# STM32F334C4T6 register map
File version: 1.0
Registers are 32-bit, access not given, reset 0x0 unless marked. A register's access mark holds for its fields unless they carry their own. Offsets are from the block's base; [hi:lo] are bit positions; {n}, {i} and the like mark numbered series; 'fields as' and 'values as' point back to an identical list.

## HRTIM1
Base 0x40017400
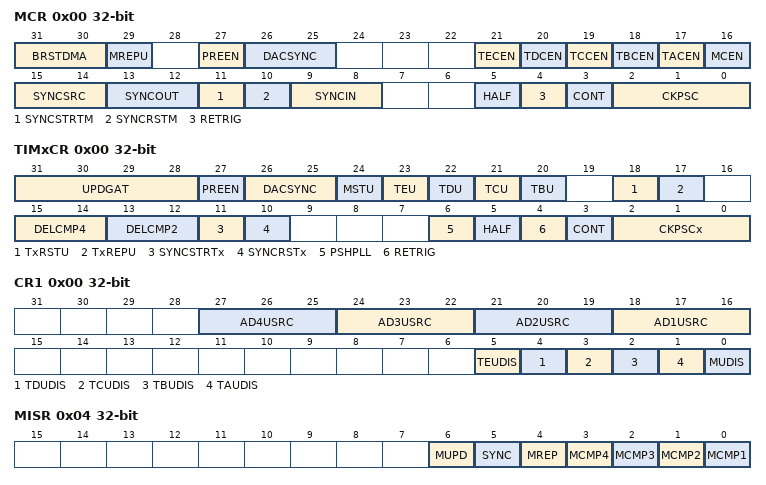
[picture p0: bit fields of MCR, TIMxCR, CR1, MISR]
0x00 MCR
  [31:30] BRSTDMA, [29] MREPU, [27] PREEN, [26:25] DACSYNC, [21] TECEN, [20] TDCEN, [19] TCCEN, [18] TBCEN, [17] TACEN, [16] MCEN, [15:14] SYNCSRC, [13:12] SYNCOUT, [11] SYNCSTRTM, [10] SYNCRSTM, [9:8] SYNCIN, [5] HALF, [4] RETRIG, [3] CONT, [2:0] CKPSC
0x00 TIMxCR
  [31:28] UPDGAT, [27] PREEN, [26:25] DACSYNC, [24] MSTU, [23] TEU, [22] TDU, [21] TCU, [20] TBU, [18] TxRSTU, [17] TxREPU, [15:14] DELCMP4, [13:12] DELCMP2, [11] SYNCSTRTx, [10] SYNCRSTx, [6] PSHPLL, [5] HALF, [4] RETRIG, [3] CONT, [2:0] CKPSCx
0x00 CR1
  [3n+15:3n+13] AD{n}USRC (n=1..4), [5] TEUDIS, [4] TDUDIS, [3] TCUDIS, [2] TBUDIS, [1] TAUDIS, [0] MUDIS
0x04 MISR
  [6] MUPD, [5] SYNC, [4] MREP, [n-1] MCMP{n} (n=1..4)
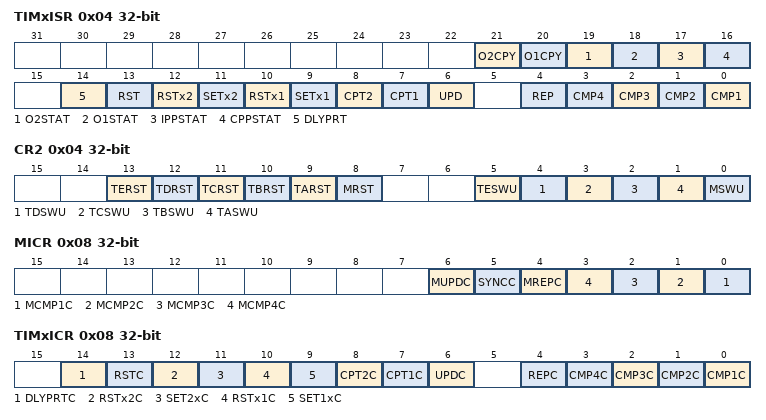
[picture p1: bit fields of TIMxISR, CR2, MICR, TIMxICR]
0x04 TIMxISR
  [21] O2CPY, [20] O1CPY, [19] O2STAT, [18] O1STAT, [17] IPPSTAT, [16] CPPSTAT, [14] DLYPRT, [13] RST, [12] RSTx2, [11] SETx2, [10] RSTx1, [9] SETx1, [8] CPT2, [7] CPT1, [6] UPD, [4] REP, [n-1] CMP{n} (n=1..4)
0x04 CR2
  [13] TERST, [12] TDRST, [11] TCRST, [10] TBRST, [9] TARST, [8] MRST, [5] TESWU, [4] TDSWU, [3] TCSWU, [2] TBSWU, [1] TASWU, [0] MSWU
0x08 MICR
  [6] MUPDC, [5] SYNCC, [4] MREPC, [n-1] MCMP{n}C (n=1..4)
0x08 TIMxICR
  [14] DLYPRTC, [13] RSTC, [12] RSTx2C, [11] SET2xC, [10] RSTx1C, [9] SET1xC, [8] CPT2C, [7] CPT1C, [6] UPDC, [4] REPC, [n-1] CMP{n}C (n=1..4)
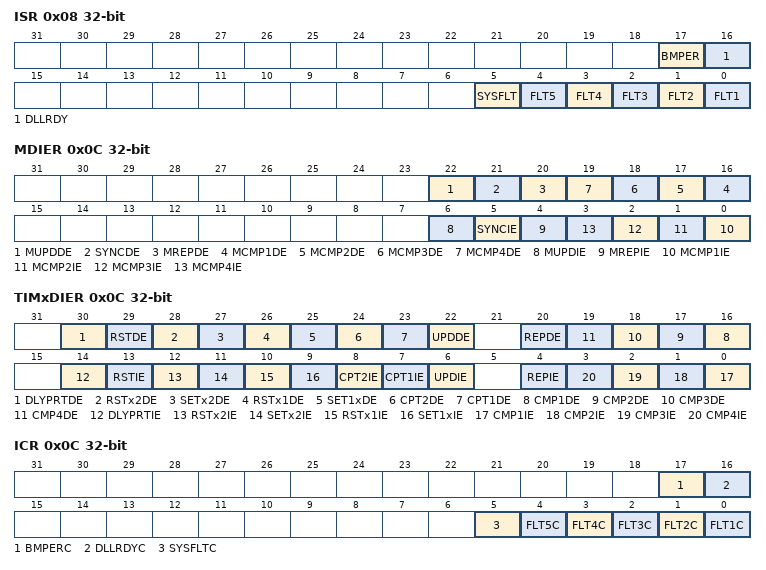
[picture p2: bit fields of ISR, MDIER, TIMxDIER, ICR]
0x08 ISR
  [17] BMPER, [16] DLLRDY, [5] SYSFLT, [n-1] FLT{n} (n=1..5)
0x0C MDIER
  [22] MUPDDE, [21] SYNCDE, [20] MREPDE, [n+15] MCMP{n}DE (n=1..4), [6] MUPDIE, [5] SYNCIE, [4] MREPIE, [n-1] MCMP{n}IE (n=1..4)
0x0C TIMxDIER
  [30] DLYPRTDE, [29] RSTDE, [28] RSTx2DE, [27] SETx2DE, [26] RSTx1DE, [25] SET1xDE, [24] CPT2DE, [23] CPT1DE, [22] UPDDE, [20] REPDE, [n+15] CMP{n}DE (n=1..4), [14] DLYPRTIE, [13] RSTIE, [12] RSTx2IE, [11] SETx2IE, [10] RSTx1IE, [9] SET1xIE, [8] CPT2IE, [7] CPT1IE, [6] UPDIE, [4] REPIE, [n-1] CMP{n}IE (n=1..4)
0x0C ICR
  [17] BMPERC, [16] DLLRDYC, [5] SYSFLTC, [n-1] FLT{n}C (n=1..5)
0x10 MCNTR
  [15:0] MCNT
0x10 CNTxR
  [15:0] CNTx
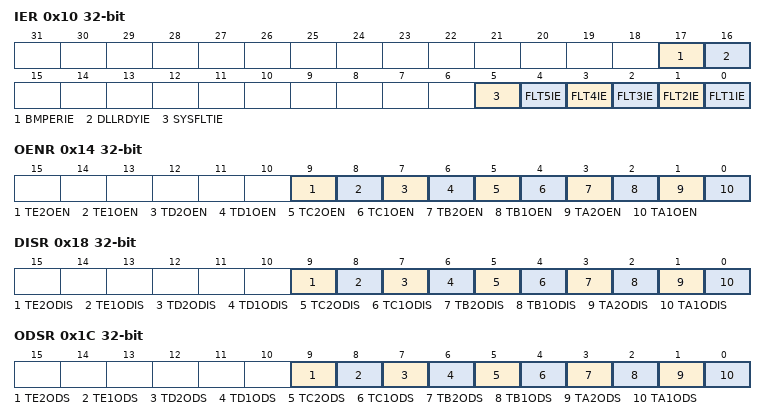
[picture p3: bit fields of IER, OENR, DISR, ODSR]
0x10 IER
  [17] BMPERIE, [16] DLLRDYIE, [5] SYSFLTIE, [n-1] FLT{n}IE (n=1..5)
0x14 MPER
  [15:0] MPER
0x14 PERxR
  [15:0] PERx
0x14 OENR
  [9] TE2OEN, [8] TE1OEN, [7] TD2OEN, [6] TD1OEN, [5] TC2OEN, [4] TC1OEN, [3] TB2OEN, [2] TB1OEN, [1] TA2OEN, [0] TA1OEN
0x18 MREP
  [7:0] MREP
0x18 REPxR
  [7:0] REPx
0x18 DISR
  [9] TE2ODIS, [8] TE1ODIS, [7] TD2ODIS, [6] TD1ODIS, [5] TC2ODIS, [4] TC1ODIS, [3] TB2ODIS, [2] TB1ODIS, [1] TA2ODIS, [0] TA1ODIS
0x1C MCMP1R
  [15:0] MCMP1
0x1C CMP1xR
  [15:0] CMP1x
0x1C ODSR
  [9] TE2ODS, [8] TE1ODS, [7] TD2ODS, [6] TD1ODS, [5] TC2ODS, [4] TC1ODS, [3] TB2ODS, [2] TB1ODS, [1] TA2ODS, [0] TA1ODS
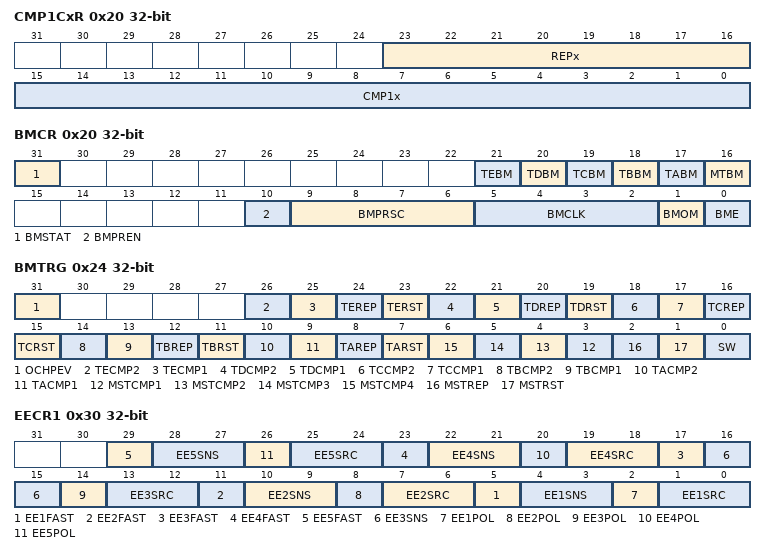
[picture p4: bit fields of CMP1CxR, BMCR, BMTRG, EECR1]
0x20 CMP1CxR
  [23:16] REPx, [15:0] CMP1x
0x20 BMCR
  [31] BMSTAT, [21] TEBM, [20] TDBM, [19] TCBM, [18] TBBM, [17] TABM, [16] MTBM, [10] BMPREN, [9:6] BMPRSC, [5:2] BMCLK, [1] BMOM, [0] BME
{0x1C+4i} MCMP{i}R (i=2..4)
  [15:0] MCMP{i}
{0x1C+4i} CMP{i}xR (i=2..4)
  [15:0] CMP{i}x
0x24 BMTRG
  [31] OCHPEV, [26] TECMP2, [25] TECMP1, [24] TEREP, [23] TERST, [22] TDCMP2, [21] TDCMP1, [20] TDREP, [19] TDRST, [18] TCCMP2, [17] TCCMP1, [16] TCREP, [15] TCRST, [14] TBCMP2, [13] TBCMP1, [12] TBREP, [11] TBRST, [10] TACMP2, [9] TACMP1, [8] TAREP, [7] TARST, [n+2] MSTCMP{n} (n=1..4), [2] MSTREP, [1] MSTRST, [0] SW
0x28 BMCMPR
  [15:0] BMCMP
0x2C BMPER
  [15:0] BMPER
0x30 CPT1xR
  [15:0] CPT1x
0x30 EECR1
  [6n-1] EE{n}FAST (n=1..5), [6n-2:6n-3] EE{n}SNS (n=1..5), [6n-4] EE{n}POL (n=1..5), [6n-5:6n-6] EE{n}SRC (n=1..5)
0x34 CPT2xR
  [15:0] CPT2x
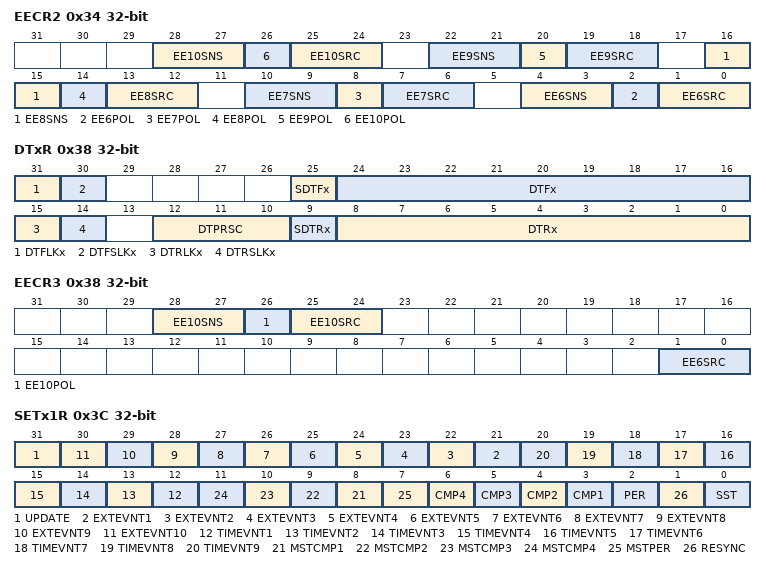
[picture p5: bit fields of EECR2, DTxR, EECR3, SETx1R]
0x34 EECR2
  [6n-32:6n-33] EE{n}SNS (n=6..10), [6n-34] EE{n}POL (n=6..10), [6n-35:6n-36] EE{n}SRC (n=6..10)
0x38 DTxR
  [31] DTFLKx, [30] DTFSLKx, [25] SDTFx, [24:16] DTFx, [15] DTRLKx, [14] DTRSLKx, [12:10] DTPRSC, [9] SDTRx, [8:0] DTRx
0x38 EECR3
  [28:27] EE10SNS, [26] EE10POL, [25:24] EE10SRC, [1:0] EE6SRC
0x3C SETx1R
  [31] UPDATE, [n+20] EXTEVNT{n} (n=1..10), [n+11] TIMEVNT{n} (n=1..9), [n+7] MSTCMP{n} (n=1..4), [7] MSTPER, [n+2] CMP{n} (n=1..4), [2] PER, [1] RESYNC, [0] SST
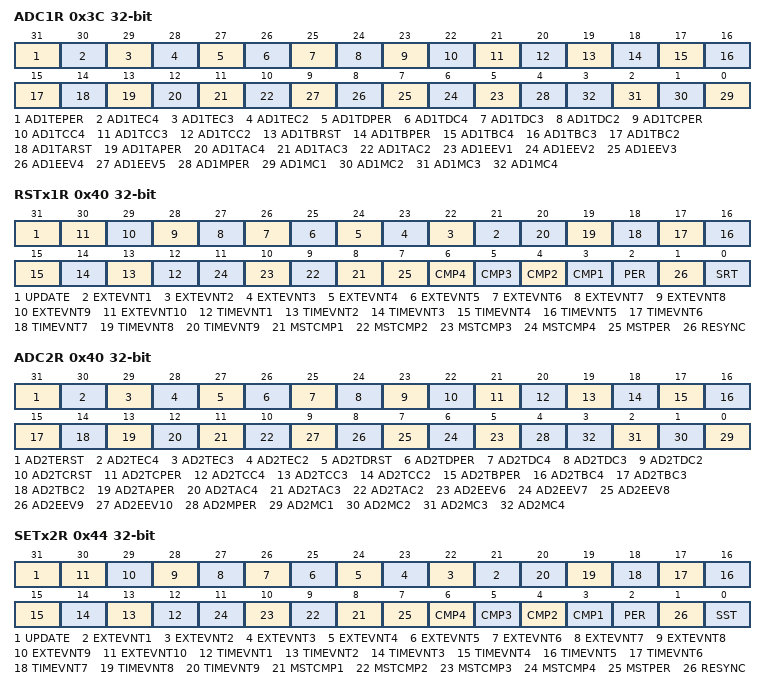
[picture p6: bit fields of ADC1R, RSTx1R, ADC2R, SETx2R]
0x3C ADC1R
  [31] AD1TEPER, [30] AD1TEC4, [29] AD1TEC3, [28] AD1TEC2, [27] AD1TDPER, [26] AD1TDC4, [25] AD1TDC3, [24] AD1TDC2, [23] AD1TCPER, [22] AD1TCC4, [21] AD1TCC3, [20] AD1TCC2, [19] AD1TBRST, [18] AD1TBPER, [17] AD1TBC4, [16] AD1TBC3, [15] AD1TBC2, [14] AD1TARST, [13] AD1TAPER, [12] AD1TAC4, [11] AD1TAC3, [10] AD1TAC2, [n+4] AD1EEV{n} (n=1..5), [4] AD1MPER, [n-1] AD1MC{n} (n=1..4)
0x40 RSTx1R
  [31] UPDATE, [n+20] EXTEVNT{n} (n=1..10), [n+11] TIMEVNT{n} (n=1..9), [n+7] MSTCMP{n} (n=1..4), [7] MSTPER, [n+2] CMP{n} (n=1..4), [2] PER, [1] RESYNC, [0] SRT
0x40 ADC2R
  [31] AD2TERST, [30] AD2TEC4, [29] AD2TEC3, [28] AD2TEC2, [27] AD2TDRST, [26] AD2TDPER, [25] AD2TDC4, [24] AD2TDC3, [23] AD2TDC2, [22] AD2TCRST, [21] AD2TCPER, [20] AD2TCC4, [19] AD2TCC3, [18] AD2TCC2, [17] AD2TBPER, [16] AD2TBC4, [15] AD2TBC3, [14] AD2TBC2, [13] AD2TAPER, [12] AD2TAC4, [11] AD2TAC3, [10] AD2TAC2, [n-1] AD2EEV{n} (n=6..10), [4] AD2MPER, [n-1] AD2MC{n} (n=1..4)
0x44 SETx2R
  fields as SETx1R
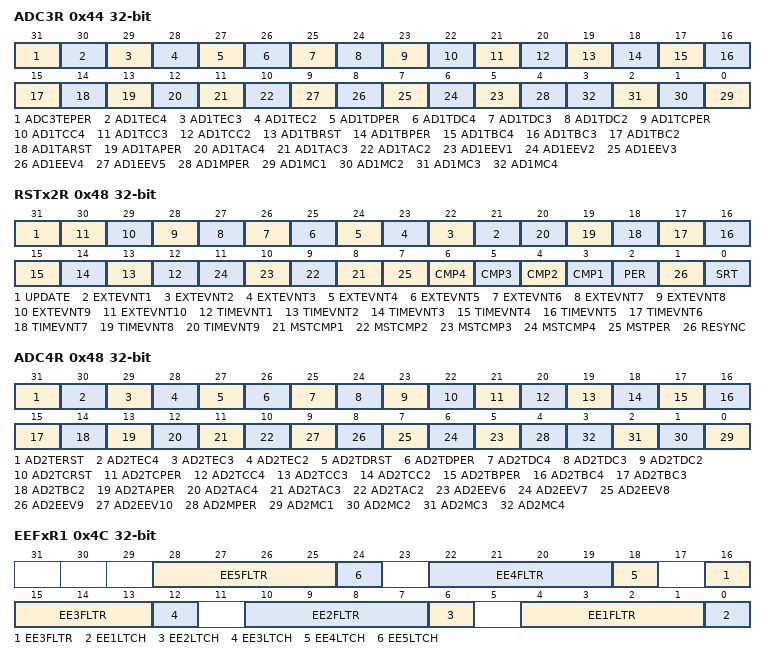
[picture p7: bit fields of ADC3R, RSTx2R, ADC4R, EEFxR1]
0x44 ADC3R
  [31] ADC3TEPER, [30] AD1TEC4, [29] AD1TEC3, [28] AD1TEC2, [27] AD1TDPER, [26] AD1TDC4, [25] AD1TDC3, [24] AD1TDC2, [23] AD1TCPER, [22] AD1TCC4, [21] AD1TCC3, [20] AD1TCC2, [19] AD1TBRST, [18] AD1TBPER, [17] AD1TBC4, [16] AD1TBC3, [15] AD1TBC2, [14] AD1TARST, [13] AD1TAPER, [12] AD1TAC4, [11] AD1TAC3, [10] AD1TAC2, [n+4] AD1EEV{n} (n=1..5), [4] AD1MPER, [n-1] AD1MC{n} (n=1..4)
0x48 RSTx2R
  fields as RSTx1R
0x48 ADC4R
  fields as ADC2R
0x4C EEFxR1
  [6n-2:6n-5] EE{n}FLTR (n=1..5), [6n-6] EE{n}LTCH (n=1..5)
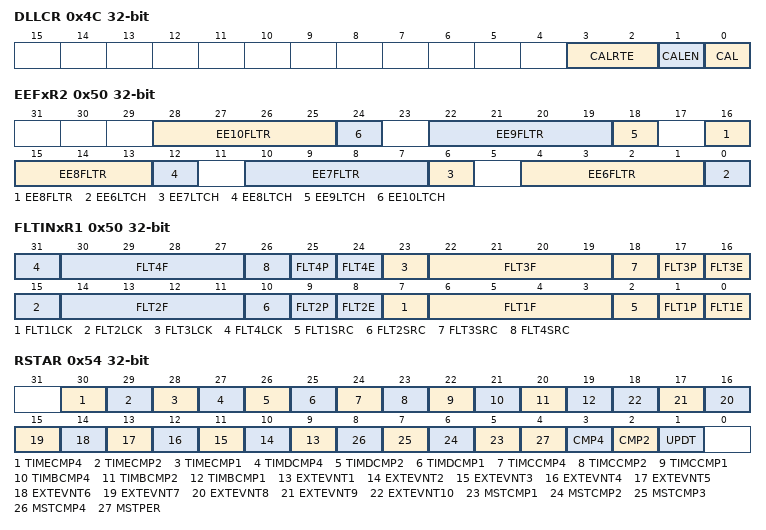
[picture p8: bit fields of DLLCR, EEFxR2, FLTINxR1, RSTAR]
0x4C DLLCR
  [3:2] CALRTE, [1] CALEN, [0] CAL
0x50 EEFxR2
  [6n-32:6n-35] EE{n}FLTR (n=6..10), [6n-36] EE{n}LTCH (n=6..10)
0x50 FLTINxR1
  [8n-1] FLT{n}LCK (n=1..4), [8n-2:8n-5] FLT{n}F (n=1..4), [8n-6] FLT{n}SRC (n=1..4), [8n-7] FLT{n}P (n=1..4), [8n-8] FLT{n}E (n=1..4)
0x54 RSTAR
  [30] TIMECMP4, [29] TIMECMP2, [28] TIMECMP1, [27] TIMDCMP4, [26] TIMDCMP2, [25] TIMDCMP1, [24] TIMCCMP4, [23] TIMCCMP2, [22] TIMCCMP1, [21] TIMBCMP4, [20] TIMBCMP2, [19] TIMBCMP1, [n+8] EXTEVNT{n} (n=1..10), [n+4] MSTCMP{n} (n=1..4), [4] MSTPER, [3] CMP4, [2] CMP2, [1] UPDT
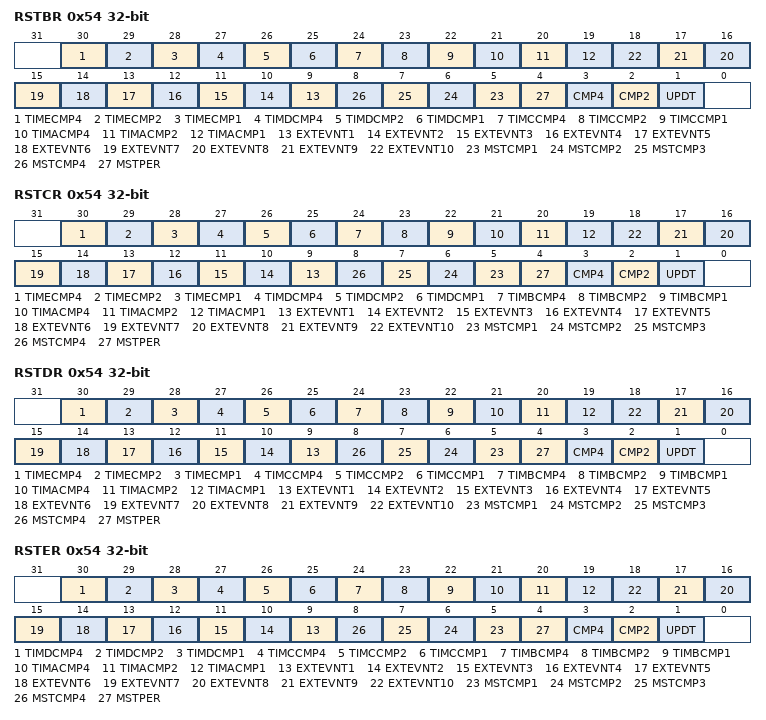
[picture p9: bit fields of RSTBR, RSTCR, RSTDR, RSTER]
0x54 RSTBR
  [30] TIMECMP4, [29] TIMECMP2, [28] TIMECMP1, [27] TIMDCMP4, [26] TIMDCMP2, [25] TIMDCMP1, [24] TIMCCMP4, [23] TIMCCMP2, [22] TIMCCMP1, [21] TIMACMP4, [20] TIMACMP2, [19] TIMACMP1, [n+8] EXTEVNT{n} (n=1..10), [n+4] MSTCMP{n} (n=1..4), [4] MSTPER, [3] CMP4, [2] CMP2, [1] UPDT
0x54 RSTCR
  [30] TIMECMP4, [29] TIMECMP2, [28] TIMECMP1, [27] TIMDCMP4, [26] TIMDCMP2, [25] TIMDCMP1, [24] TIMBCMP4, [23] TIMBCMP2, [22] TIMBCMP1, [21] TIMACMP4, [20] TIMACMP2, [19] TIMACMP1, [n+8] EXTEVNT{n} (n=1..10), [n+4] MSTCMP{n} (n=1..4), [4] MSTPER, [3] CMP4, [2] CMP2, [1] UPDT
0x54 RSTDR
  [30] TIMECMP4, [29] TIMECMP2, [28] TIMECMP1, [27] TIMCCMP4, [26] TIMCCMP2, [25] TIMCCMP1, [24] TIMBCMP4, [23] TIMBCMP2, [22] TIMBCMP1, [21] TIMACMP4, [20] TIMACMP2, [19] TIMACMP1, [n+8] EXTEVNT{n} (n=1..10), [n+4] MSTCMP{n} (n=1..4), [4] MSTPER, [3] CMP4, [2] CMP2, [1] UPDT
0x54 RSTER
  [30] TIMDCMP4, [29] TIMDCMP2, [28] TIMDCMP1, [27] TIMCCMP4, [26] TIMCCMP2, [25] TIMCCMP1, [24] TIMBCMP4, [23] TIMBCMP2, [22] TIMBCMP1, [21] TIMACMP4, [20] TIMACMP2, [19] TIMACMP1, [n+8] EXTEVNT{n} (n=1..10), [n+4] MSTCMP{n} (n=1..4), [4] MSTPER, [3] CMP4, [2] CMP2, [1] UPDT
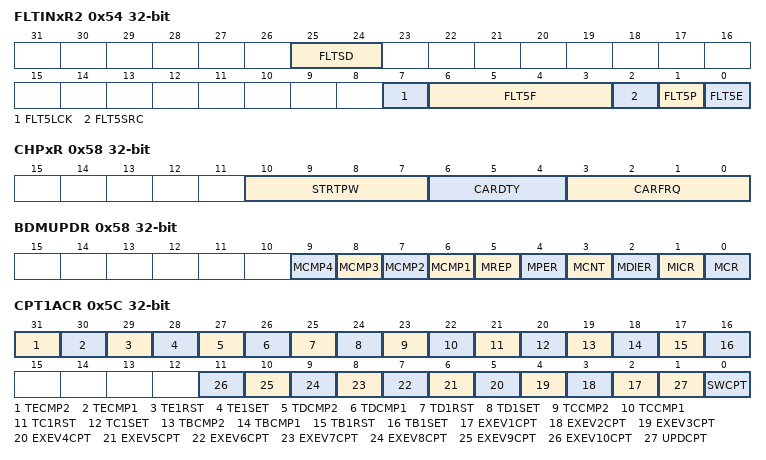
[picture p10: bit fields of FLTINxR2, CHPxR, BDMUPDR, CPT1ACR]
0x54 FLTINxR2
  [25:24] FLTSD, [7] FLT5LCK, [6:3] FLT5F, [2] FLT5SRC, [1] FLT5P, [0] FLT5E
0x58 CHPxR
  [10:7] STRTPW, [6:4] CARDTY, [3:0] CARFRQ
0x58 BDMUPDR
  [n+5] MCMP{n} (n=1..4), [5] MREP, [4] MPER, [3] MCNT, [2] MDIER, [1] MICR, [0] MCR
0x5C CPT1ACR
  [31] TECMP2, [30] TECMP1, [29] TE1RST, [28] TE1SET, [27] TDCMP2, [26] TDCMP1, [25] TD1RST, [24] TD1SET, [23] TCCMP2, [22] TCCMP1, [21] TC1RST, [20] TC1SET, [19] TBCMP2, [18] TBCMP1, [17] TB1RST, [16] TB1SET, [n+1] EXEV{n}CPT (n=1..10), [1] UPDCPT, [0] SWCPT
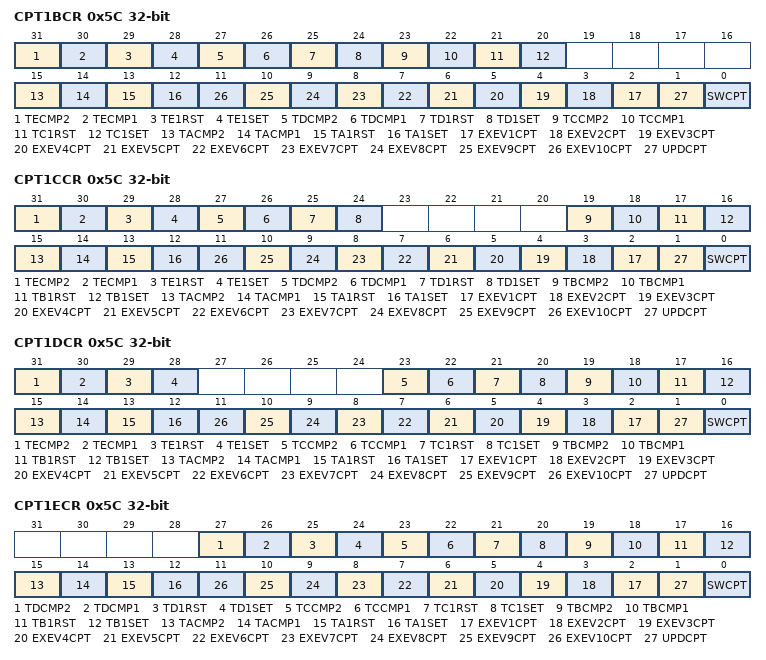
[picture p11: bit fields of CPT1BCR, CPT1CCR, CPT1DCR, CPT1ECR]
0x5C CPT1BCR
  [31] TECMP2, [30] TECMP1, [29] TE1RST, [28] TE1SET, [27] TDCMP2, [26] TDCMP1, [25] TD1RST, [24] TD1SET, [23] TCCMP2, [22] TCCMP1, [21] TC1RST, [20] TC1SET, [15] TACMP2, [14] TACMP1, [13] TA1RST, [12] TA1SET, [n+1] EXEV{n}CPT (n=1..10), [1] UPDCPT, [0] SWCPT
0x5C CPT1CCR
  [31] TECMP2, [30] TECMP1, [29] TE1RST, [28] TE1SET, [27] TDCMP2, [26] TDCMP1, [25] TD1RST, [24] TD1SET, [19] TBCMP2, [18] TBCMP1, [17] TB1RST, [16] TB1SET, [15] TACMP2, [14] TACMP1, [13] TA1RST, [12] TA1SET, [n+1] EXEV{n}CPT (n=1..10), [1] UPDCPT, [0] SWCPT
0x5C CPT1DCR
  [31] TECMP2, [30] TECMP1, [29] TE1RST, [28] TE1SET, [23] TCCMP2, [22] TCCMP1, [21] TC1RST, [20] TC1SET, [19] TBCMP2, [18] TBCMP1, [17] TB1RST, [16] TB1SET, [15] TACMP2, [14] TACMP1, [13] TA1RST, [12] TA1SET, [n+1] EXEV{n}CPT (n=1..10), [1] UPDCPT, [0] SWCPT
0x5C CPT1ECR
  [27] TDCMP2, [26] TDCMP1, [25] TD1RST, [24] TD1SET, [23] TCCMP2, [22] TCCMP1, [21] TC1RST, [20] TC1SET, [19] TBCMP2, [18] TBCMP1, [17] TB1RST, [16] TB1SET, [15] TACMP2, [14] TACMP1, [13] TA1RST, [12] TA1SET, [n+1] EXEV{n}CPT (n=1..10), [1] UPDCPT, [0] SWCPT
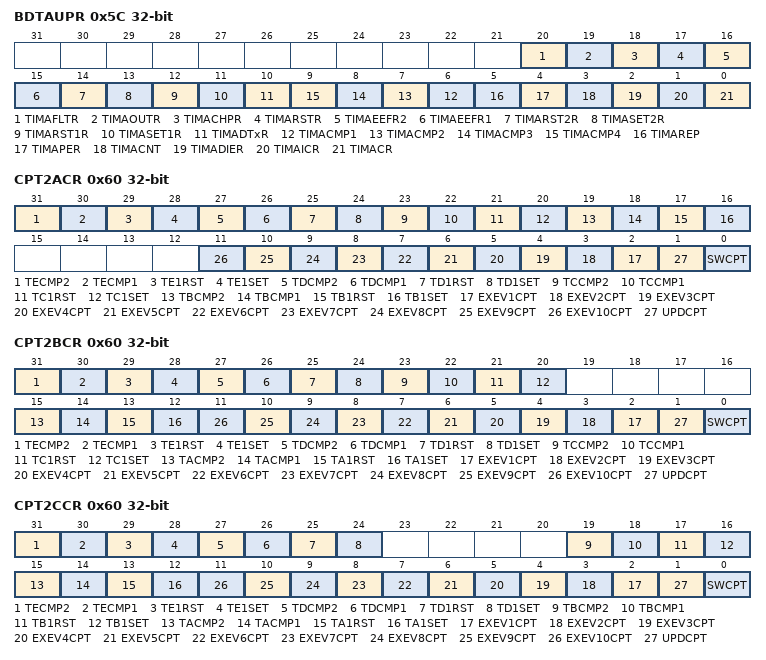
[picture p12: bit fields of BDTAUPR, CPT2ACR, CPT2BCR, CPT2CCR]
0x5C BDTAUPR
  [20] TIMAFLTR, [19] TIMAOUTR, [18] TIMACHPR, [17] TIMARSTR, [16] TIMAEEFR2, [15] TIMAEEFR1, [14] TIMARST2R, [13] TIMASET2R, [12] TIMARST1R, [11] TIMASET1R, [10] TIMADTxR, [n+5] TIMACMP{n} (n=1..4), [5] TIMAREP, [4] TIMAPER, [3] TIMACNT, [2] TIMADIER, [1] TIMAICR, [0] TIMACR
0x60 CPT2ACR
  fields as CPT1ACR
0x60 CPT2BCR
  fields as CPT1BCR
0x60 CPT2CCR
  fields as CPT1CCR
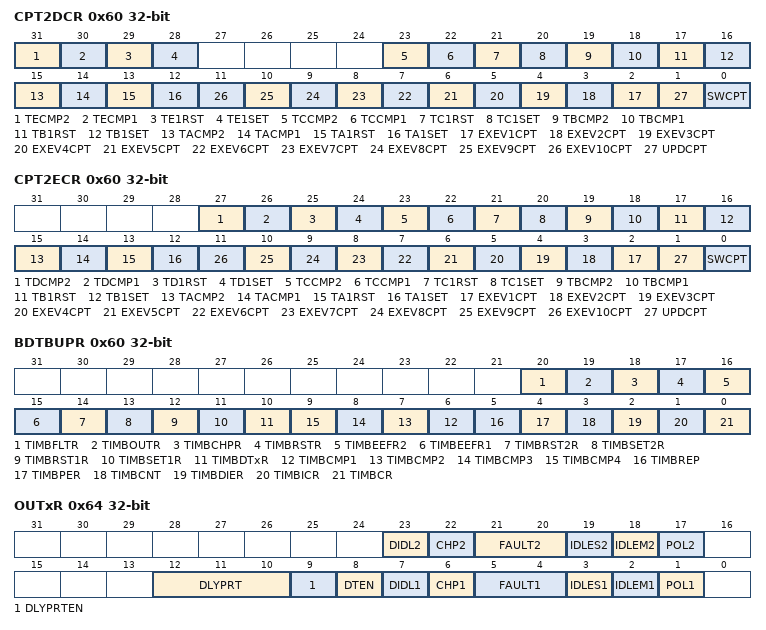
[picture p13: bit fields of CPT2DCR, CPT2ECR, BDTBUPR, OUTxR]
0x60 CPT2DCR
  fields as CPT1DCR
0x60 CPT2ECR
  fields as CPT1ECR
0x60 BDTBUPR
  [20] TIMBFLTR, [19] TIMBOUTR, [18] TIMBCHPR, [17] TIMBRSTR, [16] TIMBEEFR2, [15] TIMBEEFR1, [14] TIMBRST2R, [13] TIMBSET2R, [12] TIMBRST1R, [11] TIMBSET1R, [10] TIMBDTxR, [n+5] TIMBCMP{n} (n=1..4), [5] TIMBREP, [4] TIMBPER, [3] TIMBCNT, [2] TIMBDIER, [1] TIMBICR, [0] TIMBCR
0x64 OUTxR
  [23] DIDL2, [22] CHP2, [21:20] FAULT2, [19] IDLES2, [18] IDLEM2, [17] POL2, [12:10] DLYPRT, [9] DLYPRTEN, [8] DTEN, [7] DIDL1, [6] CHP1, [5:4] FAULT1, [3] IDLES1, [2] IDLEM1, [1] POL1
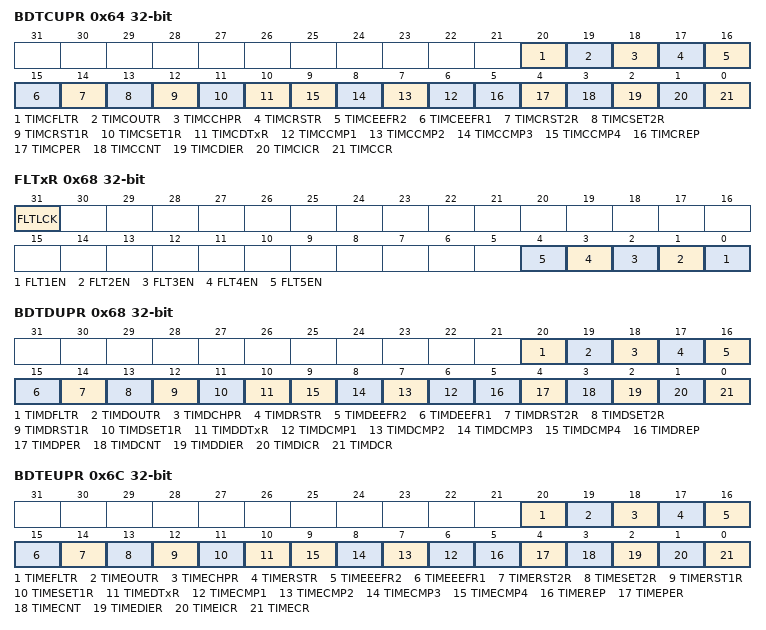
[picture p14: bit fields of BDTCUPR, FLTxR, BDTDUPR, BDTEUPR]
0x64 BDTCUPR
  [20] TIMCFLTR, [19] TIMCOUTR, [18] TIMCCHPR, [17] TIMCRSTR, [16] TIMCEEFR2, [15] TIMCEEFR1, [14] TIMCRST2R, [13] TIMCSET2R, [12] TIMCRST1R, [11] TIMCSET1R, [10] TIMCDTxR, [n+5] TIMCCMP{n} (n=1..4), [5] TIMCREP, [4] TIMCPER, [3] TIMCCNT, [2] TIMCDIER, [1] TIMCICR, [0] TIMCCR
0x68 FLTxR
  [31] FLTLCK, [n-1] FLT{n}EN (n=1..5)
0x68 BDTDUPR
  [20] TIMDFLTR, [19] TIMDOUTR, [18] TIMDCHPR, [17] TIMDRSTR, [16] TIMDEEFR2, [15] TIMDEEFR1, [14] TIMDRST2R, [13] TIMDSET2R, [12] TIMDRST1R, [11] TIMDSET1R, [10] TIMDDTxR, [n+5] TIMDCMP{n} (n=1..4), [5] TIMDREP, [4] TIMDPER, [3] TIMDCNT, [2] TIMDDIER, [1] TIMDICR, [0] TIMDCR
0x6C BDTEUPR
  [20] TIMEFLTR, [19] TIMEOUTR, [18] TIMECHPR, [17] TIMERSTR, [16] TIMEEEFR2, [15] TIMEEEFR1, [14] TIMERST2R, [13] TIMESET2R, [12] TIMERST1R, [11] TIMESET1R, [10] TIMEDTxR, [n+5] TIMECMP{n} (n=1..4), [5] TIMEREP, [4] TIMEPER, [3] TIMECNT, [2] TIMEDIER, [1] TIMEICR, [0] TIMECR
0x70 BDMADR
